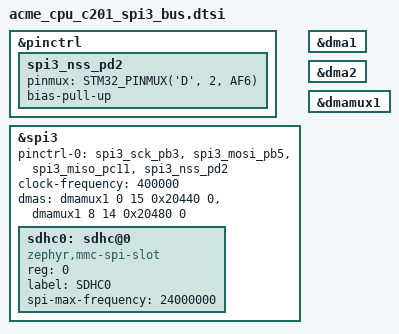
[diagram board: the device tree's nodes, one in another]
/*
	SPI3 bus connected to SD Card interface on C201 board
*/
&pinctrl {
  spi3_nss_pd2: spi3_nss_pd2 {
    pinmux = <STM32_PINMUX('D', 2, AF6)>;
    bias-pull-up;
  };
};

&spi3 {
    status = "okay";
    pinctrl-0 = <&spi3_sck_pb3 &spi3_mosi_pb5 &spi3_miso_pc11 &spi3_nss_pd2>;
	clock-frequency = <400000>;
	
	/* ref:
		rm0440 pg. 426,
		zephyr/tests/drivers/spi/spi_loopback/boards/nucleo_g474re.overlay
		st,stm32-qspi.yaml
	*/
	dmas = <&dmamux1 0 15 0x20440 0
			&dmamux1 8 14 0x20480 0>;
	dma-names = "tx", "rx";

	sdhc0: sdhc@0 {
        compatible = "zephyr,mmc-spi-slot";
        reg = <0>;
        status = "okay";
        label = "SDHC0";
        spi-max-frequency = <24000000>;
	};
};

&dma1 {
	status = "okay";
};

&dma2 {
	status = "okay";
};

&dmamux1 {
	status = "okay";
};

